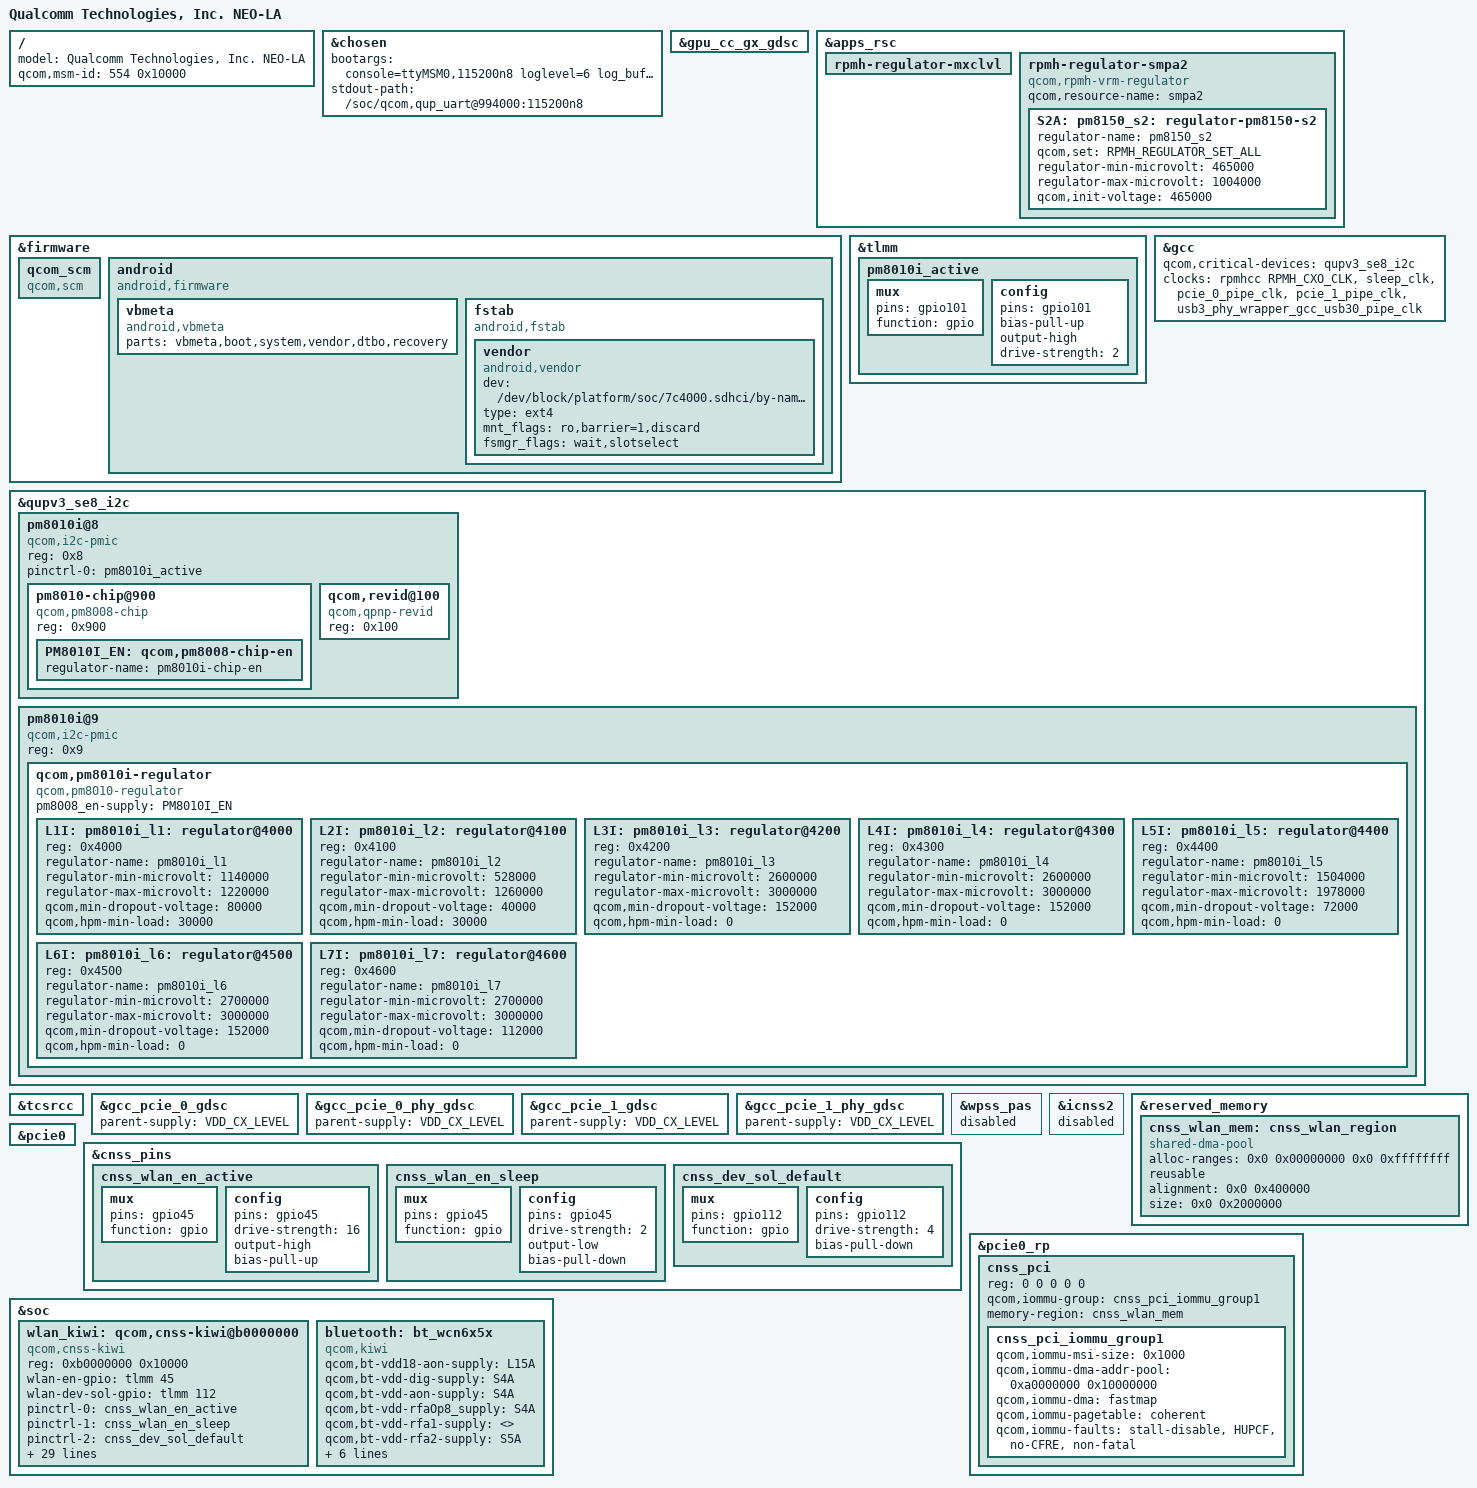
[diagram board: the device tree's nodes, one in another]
#include "neo.dtsi"
#include <dt-bindings/gpio/gpio.h>
#include <dt-bindings/clock/qcom,rpmh.h>

/ {
	model = "Qualcomm Technologies, Inc. NEO-LA";
	qcom,msm-id = <554 0x10000>;
};

&chosen {
	bootargs = "console=ttyMSM0,115200n8 loglevel=6 log_buf_len=256K kernel.panic_on_rcu_stall=1 loop.max_part=7 pcie_ports=compat service_locator.enable=1 msm_rtb.filter=0x237 allow_mismatched_32bit_el0 kasan=off rcupdate.rcu_expedited=1 rcu_nocbs=0-7 ftrace_dump_on_oops pstore.compress=none kpti=off swiotlb=noforce cgroup.memory=nokmem,nosocket allow_file_spec_access";

	stdout-path = "/soc/qcom,qup_uart@994000:115200n8";
};

&gpu_cc_gx_gdsc {
	/*
	 * Clocks uses GFX as its parent supply delete it as
	 * its not required on neo_la.
	 */
	/delete-property/ parent-supply;
};

&apps_rsc {
	/* Delete GFX rail as it is not required on neo_la platform. */
	/delete-node/ rpmh-regulator-gfxlvl;

	rpmh-regulator-mxclvl {
		/delete-node/ regulator-pm8150-s8-gfx-voter-level;
	};

	rpmh-regulator-smpa2 {
		compatible = "qcom,rpmh-vrm-regulator";
		qcom,resource-name = "smpa2";
		S2A: pm8150_s2: regulator-pm8150-s2 {
			regulator-name = "pm8150_s2";
			qcom,set = <RPMH_REGULATOR_SET_ALL>;
			regulator-min-microvolt = <465000>;
			regulator-max-microvolt = <1004000>;
			qcom,init-voltage = <465000>;
		};
	};
};

&firmware {
	qcom_scm {
		compatible = "qcom,scm";
	};

	android {
		compatible = "android,firmware";
		vbmeta {
			compatible = "android,vbmeta";
			parts = "vbmeta,boot,system,vendor,dtbo,recovery";
		};

		fstab {
			compatible = "android,fstab";
			vendor {
				compatible = "android,vendor";
				dev = "/dev/block/platform/soc/7c4000.sdhci/by-name/vendor";
				type = "ext4";
				mnt_flags = "ro,barrier=1,discard";
				fsmgr_flags = "wait,slotselect";
				status = "ok";
			};
		};
	};
};

&tlmm {
	pm8010i_active: pm8010i_active {
		mux {
			pins = "gpio101";
			function = "gpio";
		};

		config {
			pins = "gpio101";
			bias-pull-up;
			output-high;
			drive-strength = <2>;
		};
	};
};

/*
 * Each QUP device that's a parent to PMIC must be listed as a critical device
 * to GCC
 */
&gcc {
	qcom,critical-devices = <&qupv3_se8_i2c>;
};

&qupv3_se8_i2c {
	#address-cells = <1>;
	#size-cells = <0>;
	status = "ok";

	pm8010i@8 {
		compatible = "qcom,i2c-pmic";
		reg = <0x8>;
		#address-cells = <1>;
		#size-cells = <0>;

		pinctrl-names = "default";
		pinctrl-0 = <&pm8010i_active>;

		pm8010-chip@900 {
			compatible = "qcom,pm8008-chip";
			reg = <0x900>;

			PM8010I_EN: qcom,pm8008-chip-en {
				regulator-name = "pm8010i-chip-en";
			};
		};

		qcom,revid@100 {
			compatible = "qcom,qpnp-revid";
			reg = <0x100>;
		};
	};

	pm8010i@9 {
		compatible = "qcom,i2c-pmic";
		reg = <0x9>;
		#address-cells = <1>;
		#size-cells = <0>;

		qcom,pm8010i-regulator {
			compatible = "qcom,pm8010-regulator";
			#address-cells = <1>;
			#size-cells = <0>;

			pm8008_en-supply = <&PM8010I_EN>;

			L1I: pm8010i_l1: regulator@4000 {
				reg = <0x4000>;
				regulator-name = "pm8010i_l1";
				regulator-min-microvolt = <1140000>;
				regulator-max-microvolt = <1220000>;
				qcom,min-dropout-voltage = <80000>;
				qcom,hpm-min-load = <30000>;
			};

			L2I: pm8010i_l2: regulator@4100 {
				reg = <0x4100>;
				regulator-name = "pm8010i_l2";
				regulator-min-microvolt = <528000>;
				regulator-max-microvolt = <1260000>;
				qcom,min-dropout-voltage = <40000>;
				qcom,hpm-min-load = <30000>;
			};

			L3I: pm8010i_l3: regulator@4200 {
				reg = <0x4200>;
				regulator-name = "pm8010i_l3";
				regulator-min-microvolt = <2600000>;
				regulator-max-microvolt = <3000000>;
				qcom,min-dropout-voltage = <152000>;
				qcom,hpm-min-load = <0>;
			};

			L4I: pm8010i_l4: regulator@4300 {
				reg = <0x4300>;
				regulator-name = "pm8010i_l4";
				regulator-min-microvolt = <2600000>;
				regulator-max-microvolt = <3000000>;
				qcom,min-dropout-voltage = <152000>;
				qcom,hpm-min-load = <0>;
			};

			L5I: pm8010i_l5: regulator@4400 {
				reg = <0x4400>;
				regulator-name = "pm8010i_l5";
				regulator-min-microvolt = <1504000>;
				regulator-max-microvolt = <1978000>;
				qcom,min-dropout-voltage = <72000>;
				qcom,hpm-min-load = <0>;
			};

			L6I: pm8010i_l6: regulator@4500 {
				reg = <0x4500>;
				regulator-name = "pm8010i_l6";
				regulator-min-microvolt = <2700000>;
				regulator-max-microvolt = <3000000>;
				qcom,min-dropout-voltage = <152000>;
				qcom,hpm-min-load = <0>;
			};

			L7I: pm8010i_l7: regulator@4600 {
				reg = <0x4600>;
				regulator-name = "pm8010i_l7";
				regulator-min-microvolt = <2700000>;
				regulator-max-microvolt = <3000000>;
				qcom,min-dropout-voltage = <112000>;
				qcom,hpm-min-load = <0>;
			};
		};
	};
};

&tcsrcc {
	/delete-property/ protected-clocks;
};

&gcc {
	clocks = <&rpmhcc RPMH_CXO_CLK>, <&sleep_clk>,
		<&pcie_0_pipe_clk>, <&pcie_1_pipe_clk>,
		<&usb3_phy_wrapper_gcc_usb30_pipe_clk>;
	clock-names = "bi_tcxo", "sleep_clk",
		"pcie_0_pipe_clk", "pcie_1_pipe_clk",
		"usb3_phy_wrapper_gcc_usb30_pipe_clk";
	/delete-property/ protected-clocks;
};

&gcc_pcie_0_gdsc {
	parent-supply = <&VDD_CX_LEVEL>;
	status = "ok";
	/delete-property/ qcom,support-hw-trigger;
};

&gcc_pcie_0_phy_gdsc {
	parent-supply = <&VDD_CX_LEVEL>;
	status = "ok";
};

&gcc_pcie_1_gdsc {
	parent-supply = <&VDD_CX_LEVEL>;
	status = "ok";
};

&gcc_pcie_1_phy_gdsc {
	parent-supply = <&VDD_CX_LEVEL>;
	status = "ok";
};

&wpss_pas {
	status = "disabled";
	/delete-property/ memory-region;
};

&icnss2 {
	status = "disabled";
	/delete-property/ qcom,wlan-msa-fixed-region;
};

&reserved_memory {
	cnss_wlan_mem: cnss_wlan_region {
		compatible = "shared-dma-pool";
		alloc-ranges = <0x0 0x00000000 0x0 0xffffffff>;
		reusable;
		alignment = <0x0 0x400000>;
		size = <0x0 0x2000000>;
	};
};

&pcie0 {
	status = "ok";
};

&cnss_pins {
	cnss_wlan_en_active: cnss_wlan_en_active {
		mux {
			pins = "gpio45";
			function = "gpio";
		};

		config {
			pins = "gpio45";
			drive-strength = <16>;
			output-high;
			bias-pull-up;
		};
	};

	cnss_wlan_en_sleep: cnss_wlan_en_sleep {
		mux {
			pins = "gpio45";
			function = "gpio";
		};

		config {
			pins = "gpio45";
			drive-strength = <2>;
			output-low;
			bias-pull-down;
		};
	};

	cnss_dev_sol_default: cnss_dev_sol_default {
		mux {
			pins = "gpio112";
			function = "gpio";
		};

		config {
			pins = "gpio112";
			drive-strength = <4>;
			bias-pull-down;
		};
	};
};

&soc {
	wlan_kiwi: qcom,cnss-kiwi@b0000000 {
		compatible = "qcom,cnss-kiwi";
		reg = <0xb0000000 0x10000>;
		reg-names = "smmu_iova_ipa";
		wlan-en-gpio = <&tlmm 45 0>;
		wlan-dev-sol-gpio = <&tlmm 112 0>;
		pinctrl-names = "wlan_en_active", "wlan_en_sleep",
				"sol_default";
		pinctrl-0 = <&cnss_wlan_en_active>;
		pinctrl-1 = <&cnss_wlan_en_sleep>;
		pinctrl-2 = <&cnss_dev_sol_default>;
		qcom,wlan;
		qcom,wlan-rc-num = <0>;
		qcom,wlan-ramdump-dynamic = <0x780000>;
		qcom,wlan-cbc-enabled;
		use-pm-domain;
		qcom,same-dt-multi-dev;
		mboxes = <&qmp_aop 0>;

		vdd-wlan-io-supply = <&L15A>;
		qcom,vdd-wlan-io-config = <1800000 2000000 0 0 0>;
		vdd-wlan-supply = <&S2A>;
		qcom,vdd-wlan-config = <1000000 1004000 0 0 0>;
		vdd-wlan-aon-supply = <&S4A>;
		qcom,vdd-wlan-aon-config = <980000 1170000 0 0 1>;
		vdd-wlan-dig-supply = <&S5A>;
		qcom,vdd-wlan-dig-config = <1900000 2040000 0 0 1>;

		interconnects =
		<&pcie_noc MASTER_PCIE_0 &pcie_noc SLAVE_ANOC_PCIE_GEM_NOC>,
		<&gem_noc MASTER_ANOC_PCIE_GEM_NOC &mc_virt SLAVE_EBI1>;
		interconnect-names = "pcie_to_memnoc", "memnoc_to_ddr";

		qcom,icc-path-count = <2>;
		qcom,bus-bw-cfg-count = <9>;
		qcom,bus-bw-cfg =
		/** ICC Path 1 **/
		<0 0>, /* no vote */
		/* idle: 0-18 Mbps snoc/anoc: 100 Mhz */
		<2250 1600000>,
		/* low: 18-60 Mbps snoc/anoc: 100 Mhz */
		<7500 1600000>,
		/* medium: 60-240 Mbps snoc/anoc: 100 Mhz*/
		<30000 1600000>,
		/* high: 240-1200 Mbps snoc/anoc: 200 Mhz */
		<100000 3200000>,
		/* very high: > 1200 Mbps snoc/anoc: 403 Mhz */
		<175000 6553200>,
		/* ultra high: DBS mode snoc/anoc: 403 Mhz */
		<175000 6553200>,
		/* super high: DBS mode snoc/anoc: 403 Mhz */
		<175000 6553200>,
		/* low (latency critical): 18-60 Mbps snoc/anoc: 200 Mhz */
		<7500 3200000>,

		/** ICC Path 2 **/
		<0 0>,
		/* ddr: 451.2 MHz */
		<2250 902212>,
		/* ddr: 451.2 MHz */
		<7500 902212>,
		/* ddr: 451.2 MHz */
		<30000 902212>,
		/* ddr: 451.2 MHz */
		<100000 902212>,
		/* ddr: 1555 MHz */
		<175000 3110362>,
		/* ddr: 2092 MHz */
		<175000 4185562>,
		/* ddr: 2133 MHz */
		<175000 4300537>,
		/* ddr: 547.2 MHz */
		<7500 1094362>;

	};

	bluetooth: bt_wcn6x5x {
		compatible = "qcom,kiwi";
		qcom,bt-vdd18-aon-supply  = <&L15A>; /* BT VDD1.8 AON */
		qcom,bt-vdd-dig-supply    = <&S4A>; /* BT LDO*/
		qcom,bt-vdd-aon-supply    = <&S4A>; /* BT AON LDO*/
		qcom,bt-vdd-rfaOp8_supply = <&S4A>; /* BT RFAOp8 CMN LDO*/
		qcom,bt-vdd-rfa1-supply   = <>;   /* BT RFA1.2 LDO. always ON */
		qcom,bt-vdd-rfa2-supply   = <&S5A>; /* BT RFA1.8 LDO */

		qcom,bt-vdd18-aon-config  = <1800000 1800000 0 1>;
		qcom,bt-vdd-aon-config    = <950000 950000 0 1>;
		qcom,bt-vdd-dig-config    = <950000 950000 0 1>;
		qcom,bt-vdd-rfaOp8-config = <950000 950000 0 1>;
		qcom,bt-vdd-rfa1-config   = <1350000 1350000 0 1>;
		qcom,bt-vdd-rfa2-config   = <1900000 1900000 0 1>;
	};
};

&pcie0_rp {
	#address-cells = <5>;
	#size-cells = <0>;

	cnss_pci: cnss_pci {
		reg = <0 0 0 0 0>;
		qcom,iommu-group = <&cnss_pci_iommu_group1>;
		memory-region = <&cnss_wlan_mem>;

		#address-cells = <1>;
		#size-cells = <1>;

		cnss_pci_iommu_group1: cnss_pci_iommu_group1 {
			qcom,iommu-msi-size = <0x1000>;
			qcom,iommu-dma-addr-pool = <0xa0000000 0x10000000>;
			qcom,iommu-dma = "fastmap";
			qcom,iommu-pagetable = "coherent";
			qcom,iommu-faults = "stall-disable", "HUPCF", "no-CFRE",
					    "non-fatal";
		};
	};
};

#include "neo_la-reserved-memory.dtsi"
